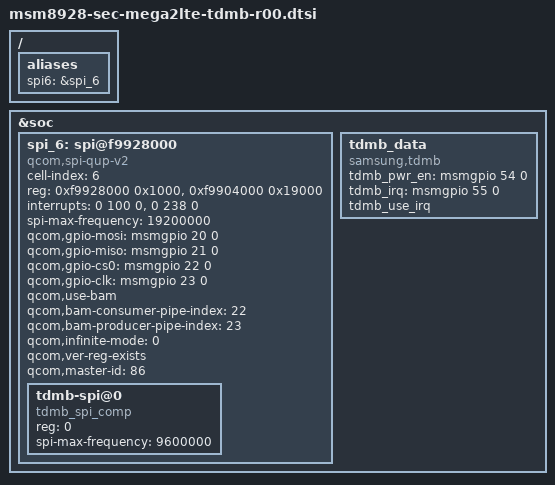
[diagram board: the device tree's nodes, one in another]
/* Copyright (c) 2012-2013, The Linux Foundation. All rights reserved.
 *
 * This program is free software; you can redistribute it and/or modify
 * it under the terms of the GNU General Public License version 2 and
 * only version 2 as published by the Free Software Foundation.
 *
 * This program is distributed in the hope that it will be useful,
 * but WITHOUT ANY WARRANTY; without even the implied warranty of
 * MERCHANTABILITY or FITNESS FOR A PARTICULAR PURPOSE.  See the
 * GNU General Public License for more details.
 */

/{
	aliases {
		spi6 = &spi_6;
	};
};

&soc {
	spi_6: spi@f9928000 {
		compatible = "qcom,spi-qup-v2";
		cell-index = <6>;
		#address-cells = <1>;
		#size-cells = <0>;
		reg-names = "spi_physical", "spi_bam_physical";
		reg = <0xf9928000 0x1000>, <0xf9904000 0x19000>;
		interrupt-names = "spi_irq", "spi_bam_irq";
		interrupts = <0 100 0>, <0 238 0>;
		spi-max-frequency = <19200000>;

		qcom,gpio-mosi = <&msmgpio 20 0>;
		qcom,gpio-miso = <&msmgpio 21 0>;
		qcom,gpio-cs0 = <&msmgpio 22 0>;
		qcom,gpio-clk = <&msmgpio 23 0>;

		qcom,use-bam;
		qcom,bam-consumer-pipe-index = <22>;
		qcom,bam-producer-pipe-index = <23>;
		qcom,infinite-mode = <0>;
		qcom,ver-reg-exists;

		qcom,master-id = <86>;

		tdmb-spi@0 {
			compatible = "tdmb_spi_comp";
			reg = <0>;
			spi-max-frequency = <9600000>;

		};
	};

	tdmb_data {
		compatible = "samsung,tdmb";
		tdmb_pwr_en = <&msmgpio 54 0>;
		tdmb_irq = <&msmgpio 55 0>;
		tdmb_use_irq;
	};

};
